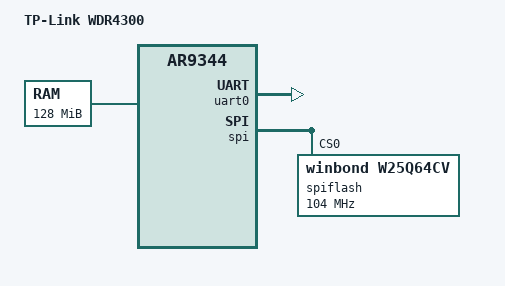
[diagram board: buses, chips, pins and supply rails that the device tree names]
/dts-v1/;

#include <dt-bindings/gpio/gpio.h>
#include <dt-bindings/input/input.h>

#include "ar9344.dtsi"

/ {
	model = "TP-Link WDR4300";
	compatible = "tplink,tl-wdr4300";

	aliases {
		serial0 = &uart0;
	};

	memory@0 {
		device_type = "memory";
		reg = <0x0 0x8000000>;
	};

	chosen {
		stdout-path = &uart0;
	};
};

&ref {
	clock-frequency = <40000000>;
};

&uart0 {
	status = "okay";
	clock-frequency = <40000000>;
};

&spi {
	num-chipselects = <1>;
	status = "okay";

	/* Winbond W25Q64CV SPI flash */
	spiflash: w25q64cv@0 {
		#address-cells = <1>;
		#size-cells = <1>;
		compatible = "winbond,w25q64cv", "jedec,spi-nor";
		spi-max-frequency = <104000000>;
		reg = <0>;
	};
};
